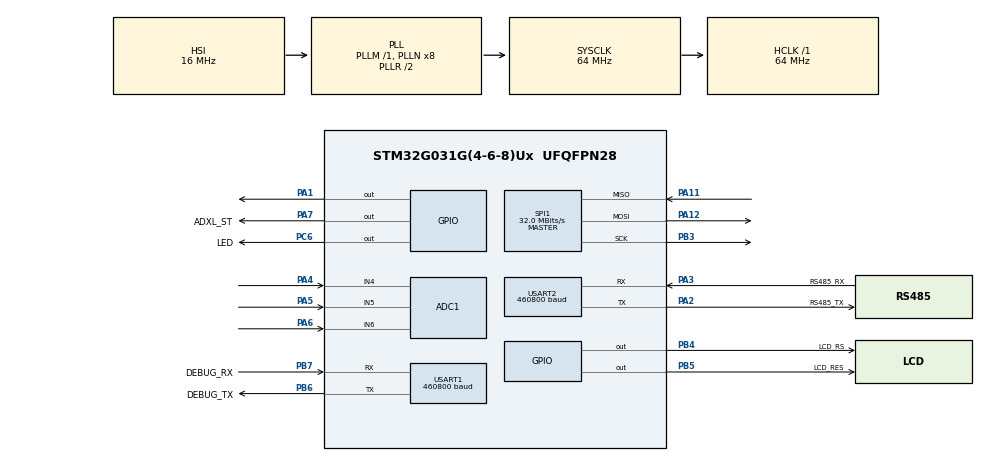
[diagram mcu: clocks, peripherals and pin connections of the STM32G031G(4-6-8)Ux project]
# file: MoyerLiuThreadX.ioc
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ADC1.ClockPrescaler=ADC_CLOCK_SYNC_PCLK_DIV2
ADC1.DMAContinuousRequests=ENABLE
ADC1.EnableAnalogWatchDog1=false
ADC1.ExternalTrigConv=ADC_EXTERNALTRIG_T2_TRGO
ADC1.NbrOfConversion=1
ADC1.NbrOfConversionFlag=0
ADC1.SamplingTimeCommon1=ADC_SAMPLETIME_79CYCLES_5
ADC1.SelectedChannel=ADC_CHANNEL_4|ADC_CHANNEL_5|ADC_CHANNEL_6|ADC_CHANNEL_VREFINT
ADC1.Sequencer=NOT_FULLY_CONFIGURABLE
ADC1.master=1
Dma.ADC1.0.Direction=DMA_PERIPH_TO_MEMORY
Dma.ADC1.0.EventEnable=DISABLE
Dma.ADC1.0.Instance=DMA1_Channel1
Dma.ADC1.0.MemDataAlignment=DMA_MDATAALIGN_HALFWORD
Dma.ADC1.0.MemInc=DMA_MINC_ENABLE
Dma.ADC1.0.Mode=DMA_CIRCULAR
Dma.ADC1.0.PeriphDataAlignment=DMA_PDATAALIGN_HALFWORD
Dma.ADC1.0.PeriphInc=DMA_PINC_DISABLE
Dma.ADC1.0.Polarity=HAL_DMAMUX_REQ_GEN_RISING
Dma.ADC1.0.Priority=DMA_PRIORITY_VERY_HIGH
Dma.ADC1.0.RequestNumber=1
Dma.ADC1.0.SignalID=NONE
Dma.ADC1.0.SyncEnable=DISABLE
Dma.ADC1.0.SyncPolarity=HAL_DMAMUX_SYNC_NO_EVENT
Dma.ADC1.0.SyncRequestNumber=1
Dma.ADC1.0.SyncSignalID=NONE
Dma.Request0=ADC1
Mcu.Family=STM32G0
Mcu.Name=STM32G031G(4-6-8)Ux
Mcu.Package=UFQFPN28
NVIC.ADC1_IRQn=true\:0\:0\:false\:false\:true\:false\:true\:true\:true
NVIC.DMA1_Channel1_IRQn=true\:0\:0\:false\:false\:true\:false\:false\:true\:true
NVIC.TIM17_IRQn=true\:3\:0\:false\:false\:true\:false\:false\:true\:true
NVIC.TIM2_IRQn=true\:0\:0\:false\:false\:true\:false\:true\:true\:true
NVIC.TimeBase=TIM17_IRQn
NVIC.TimeBaseIP=TIM17
PA1.GPIO_PuPd=GPIO_PULLUP
PA1.PinState=GPIO_PIN_SET
PA1.Signal=GPIO_Output
PA11\ [PA9].Mode=Full_Duplex_Master
PA11\ [PA9].Signal=SPI1_MISO
PA12\ [PA10].Mode=Full_Duplex_Master
PA12\ [PA10].Signal=SPI1_MOSI
PA13.Mode=Serial_Wire
PA13.Signal=SYS_SWDIO
PA14-BOOT0.Mode=Serial_Wire
PA14-BOOT0.Signal=SYS_SWCLK
PA2.GPIO_Label=RS485_TX
PA2.Mode=Asynchronous
PA2.Signal=USART2_TX
PA3.GPIO_Label=RS485_RX
PA3.Mode=Asynchronous
PA3.Signal=USART2_RX
PA4.Mode=IN4
PA4.Signal=ADC1_IN4
PA5.Mode=IN5
PA5.Signal=ADC1_IN5
PA6.Mode=IN6
PA6.Signal=ADC1_IN6
PA7.GPIO_Label=ADXL_ST
PA7.GPIO_ModeDefaultOutputPP=GPIO_MODE_OUTPUT_PP
PA7.GPIO_PuPd=GPIO_PULLDOWN
PA7.GPIO_Speed=GPIO_SPEED_FREQ_LOW
PA7.PinState=GPIO_PIN_RESET
PA7.Signal=GPIO_Output
PB3.Mode=Full_Duplex_Master
PB3.Signal=SPI1_SCK
PB4.GPIO_Label=LCD_RS
PB4.GPIO_Speed=GPIO_SPEED_FREQ_VERY_HIGH
PB4.Signal=GPIO_Output
PB5.GPIO_Label=LCD_RES
PB5.GPIO_Speed=GPIO_SPEED_FREQ_VERY_HIGH
PB5.Signal=GPIO_Output
PB6.GPIO_Label=DEBUG_TX
PB6.Mode=Asynchronous
PB6.Signal=USART1_TX
PB7.GPIO_Label=DEBUG_RX
PB7.Mode=Asynchronous
PB7.Signal=USART1_RX
PC14-OSC32_IN\ (PC14).Mode=LSE-External-Oscillator
PC14-OSC32_IN\ (PC14).Signal=RCC_OSC32_IN
PC15-OSC32_OUT\ (PC15).Mode=LSE-External-Oscillator
PC15-OSC32_OUT\ (PC15).Signal=RCC_OSC32_OUT
PC6.GPIO_Label=LED
PC6.GPIO_PuPd=GPIO_PULLUP
PC6.GPIO_Speed=GPIO_SPEED_FREQ_VERY_HIGH
PC6.PinState=GPIO_PIN_SET
PC6.Signal=GPIO_Output
ProjectManager.HeapSize=0x400
ProjectManager.StackSize=0x200
ProjectManager.TargetToolchain=MDK-ARM V5.32
RCC.ADCFreq_Value=64000000
RCC.AHBFreq_Value=64000000
RCC.CortexFreq_Value=64000000
RCC.EXTERNAL_CLOCK_VALUE=12288000
RCC.HCLKFreq_Value=64000000
RCC.HSE_VALUE=8000000
RCC.HSI_VALUE=16000000
RCC.SYSCLKFreq_VALUE=64000000
RCC.SYSCLKSource=RCC_SYSCLKSOURCE_PLLCLK
RCC.VCOOutputFreq_Value=128000000
SPI1.CalculateBaudRate=32.0 MBits/s
SPI1.Direction=SPI_DIRECTION_2LINES
SPI1.Mode=SPI_MODE_MASTER
SPI1.VirtualType=VM_MASTER
STMicroelectronics.X-CUBE-ALGOBUILD.1.3.0.LibraryCcDSPOoLibraryJjDSPOoLibrary=true
STMicroelectronics.X-CUBE-AZRTOS-G0.1.1.0.AZRTOS_APP_MEM_ALLOCATION_METHOD=0
STMicroelectronics.X-CUBE-AZRTOS-G0.1.1.0.TX_APP_MEM_POOL_SIZE=512
STMicroelectronics.X-CUBE-AZRTOS-G0.1.1.0.TX_TIMER_THREAD_STACK_SIZE=200
STMicroelectronics.X-CUBE-AZRTOS-G0.1.1.0.TX_TIMER_TICKS_PER_SECOND=1000
STMicroelectronics.X-CUBE-AZRTOS-G0.1.1.0.ThreadXCcRTOSJjThreadXJjCore=true
STMicroelectronics.X-CUBE-AZRTOS-G0.1.1.0.ThreadXCcRTOSJjThreadXJjPerformanceInfo=true
STMicroelectronics.X-CUBE-AZRTOS-G0.1.1.0.ThreadXCcRTOSJjThreadXJjTraceXOosupport=true
STMicroelectronics.X-CUBE-AZRTOS-G0.1.1.0_IsAnAzureRtosMw=true
TIM2.AutoReloadPreload=TIM_AUTORELOAD_PRELOAD_DISABLE
TIM2.Channel-PWM\ Generation1\ No\ Output=TIM_CHANNEL_1
TIM2.Period=1000-1
TIM2.Prescaler=64-1
TIM2.Pulse-PWM\ Generation1\ No\ Output=125-1
TIM2.TIM_MasterOutputTrigger=TIM_TRGO_UPDATE
USART1.BaudRate=460800
USART1.VirtualMode-Asynchronous=VM_ASYNC
USART2.BaudRate=460800
USART2.VirtualMode-Asynchronous=VM_ASYNC
VP_ADC1_Vref_Input.Mode=IN-Vrefint
VP_STMicroelectronics.X-CUBE-ALGOBUILD_VS_DSPOoLibraryJjLibrary_1.3.0_1.3.0.Mode=DSPOoLibraryJjLibrary
VP_STMicroelectronics.X-CUBE-AZRTOS-G0_VS_RTOSJjThreadX_6.1.10_1.1.0.Mode=RTOSJjThreadX
VP_SYS_VS_tim17.Mode=TIM17
VP_TIM2_VS_ClockSourceINT.Mode=Internal
VP_TIM2_VS_no_output1.Mode=PWM Generation1 No Output
board=custom

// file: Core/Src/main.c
/* USER CODE BEGIN Header */
/**
  ******************************************************************************
  * @file           : main.c
  * @brief          : Main program body
  ******************************************************************************
  * @attention
  *
  * Copyright (c) 2023 STMicroelectronics.
  * All rights reserved.
  *
  * This software is licensed under terms that can be found in the LICENSE file
  * in the root directory of this software component.
  * If no LICENSE file comes with this software, it is provided AS-IS.
  *
  ******************************************************************************
  */
/* USER CODE END Header */
#include "app_threadx.h"
#include "main.h"
#include "adc.h"
#include "dma.h"
#include "spi.h"
#include "tim.h"
#include "usart.h"
#include "gpio.h"

/* USER CODE BEGIN Includes */
#include "arm_math.h"
//#include "arm_const_stucts.h"
//#include "stm32_dsp.h"
//#include "table_fft.h"
/* USER CODE END Includes */

/* USER CODE BEGIN PD */
//#define ADC_FFT_frame 512

/* USER CODE END PD */

/* USER CODE BEGIN PM */
// char debug_buf[128];

//float32_t Vibrate_Buf[VIBBufSize];
//float32_t Vibrate_Out[VIBBufSize];
//  uint16_t ADC_Out[128];
uint16_t ADCs_Value[4];
float data = 0;
//#define  FFT_LENGTH        256        //FFT长度
//#define  SAMPLE_FREQ       2000        //采样频率

//float fft_inputbuf[FFT_LENGTH * 2];    //FFT输入输出数组，此数组为arm_cfft_radix4_f32的输入输出数组，前一个元素为实部，后一个为虚部，每两个元素代表一个点.
//float fft_outputbuf[FFT_LENGTH];       //arm_cmplx_mag_f32()幅度输出数组
//arm_cfft_radix4_instance_f32 scfft;    //fft变换的初始化参数
//arm_cfft_radix4_instance_f32 arm_cfft_sR_f32_len256;
/* USER CODE END PM */

void SystemClock_Config(void);

int main(void)
{

  /* MCU Configuration--------------------------------------------------------*/

  /* Reset of all peripherals, Initializes the Flash interface and the Systick. */
  HAL_Init();

  /* Configure the system clock */
  SystemClock_Config();

  /* Initialize all configured peripherals */
  MX_GPIO_Init();
  MX_DMA_Init();
  MX_ADC1_Init();
  MX_USART1_UART_Init();
  MX_USART2_UART_Init();
  MX_SPI1_Init();
  MX_TIM2_Init();
  /* USER CODE BEGIN 2 */
    HAL_TIM_Base_Start_IT(&htim2);
    HAL_TIM_PWM_Start(&htim2, TIM_CHANNEL_1);
    HAL_ADC_Start_DMA(&hadc1, (uint32_t*)ADCs_Value, 4);

//    while(1) {
//data=arm_sin_f32(3.1415926/6);

//cr4_fft_256_stm32(ADC_Out, ADC_Value, 256);
////////    data++;
////////    memcpy(Vibrate_Buf, Vibrate_Buf + 1, (VIBBufSize)*sizeof(float32_t));
////////    if(data>2000){
////////            arm_cfft_f32(&arm_cfft_sR_f32_len256, Vibrate_Buf, 0, 1);
////////        arm_cmplx_mag_f32(Vibrate_Buf, Vibrate_Out, 128);//求复数模
////////        data=0;
////////        }
////////    }
////        if(data > 513) {
////            ;
////            arm_cfft_radix4_init_f32(&scfft, FFT_LENGTH, 0, 1); //初始化scfft结构体，设定FFT相关参数
////            for(int i = 0; i < FFT_LENGTH; i++) //生成信号序列
////            {
////                fft_inputbuf[2 * i] = 15 + 10 * arm_sin_f32(2 * PI * i * 100 / SAMPLE_FREQ) + \
////                                      5.5 * arm_sin_f32(2 * PI * i * 150 / SAMPLE_FREQ); //生成实部
////                fft_inputbuf[2 * i + 1] = 0; //虚部全部为0
////            }
////            arm_cfft_radix4_f32(&scfft, fft_inputbuf);   //FFT计算（基4（即fft长度22*n），FFT长度只能为64，256，1024，4096目前测试过这几个长度,）
////            arm_cmplx_mag_f32(fft_inputbuf, fft_outputbuf, FFT_LENGTH);
////            data=0;//把运算结果复数求模得幅值}
////        }
//    }
  /* USER CODE END 2 */

  MX_ThreadX_Init();

  /* We should never get here as control is now taken by the scheduler */
  /* Infinite loop */
    while(1)
    {

    }
}

void SystemClock_Config(void)
{
  RCC_OscInitTypeDef RCC_OscInitStruct = {0};
  RCC_ClkInitTypeDef RCC_ClkInitStruct = {0};

  /** Configure the main internal regulator output voltage
  */
  HAL_PWREx_ControlVoltageScaling(PWR_REGULATOR_VOLTAGE_SCALE1);

  /** Initializes the RCC Oscillators according to the specified parameters
  * in the RCC_OscInitTypeDef structure.
  */
  RCC_OscInitStruct.OscillatorType = RCC_OSCILLATORTYPE_HSI;
  RCC_OscInitStruct.HSIState = RCC_HSI_ON;
  RCC_OscInitStruct.HSIDiv = RCC_HSI_DIV1;
  RCC_OscInitStruct.HSICalibrationValue = RCC_HSICALIBRATION_DEFAULT;
  RCC_OscInitStruct.PLL.PLLState = RCC_PLL_ON;
  RCC_OscInitStruct.PLL.PLLSource = RCC_PLLSOURCE_HSI;
  RCC_OscInitStruct.PLL.PLLM = RCC_PLLM_DIV1;
  RCC_OscInitStruct.PLL.PLLN = 8;
  RCC_OscInitStruct.PLL.PLLP = RCC_PLLP_DIV2;
  RCC_OscInitStruct.PLL.PLLQ = RCC_PLLQ_DIV2;
  RCC_OscInitStruct.PLL.PLLR = RCC_PLLR_DIV2;
  if (HAL_RCC_OscConfig(&RCC_OscInitStruct) != HAL_OK)
  {
    Error_Handler();
  }

  /** Initializes the CPU, AHB and APB buses clocks
  */
  RCC_ClkInitStruct.ClockType = RCC_CLOCKTYPE_HCLK|RCC_CLOCKTYPE_SYSCLK
                              |RCC_CLOCKTYPE_PCLK1;
  RCC_ClkInitStruct.SYSCLKSource = RCC_SYSCLKSOURCE_PLLCLK;
  RCC_ClkInitStruct.AHBCLKDivider = RCC_SYSCLK_DIV1;
  RCC_ClkInitStruct.APB1CLKDivider = RCC_HCLK_DIV1;

  if (HAL_RCC_ClockConfig(&RCC_ClkInitStruct, FLASH_LATENCY_2) != HAL_OK)
  {
    Error_Handler();
  }
}

void HAL_TIM_PeriodElapsedCallback(TIM_HandleTypeDef *htim)
{
  /* USER CODE BEGIN Callback 0 */
    int TempX=ADCs_Value[0],TempY=ADCs_Value[1],TempZ=ADCs_Value[2];
            printf("%c%c%c%c%c%c",
               (TempX +4096) >> 8, TempX & 0xFF,
               (TempY )>> 8, TempY & 0xFF,
               (TempZ )>> 8, TempZ & 0xFF);
  /* USER CODE END Callback 0 */
  if (htim->Instance == TIM17) {
    HAL_IncTick();
  }
}

void Error_Handler(void)
{
    __disable_irq();
    while(1)
    {
    }
}
